# CY8C4248AZI_L485 register map
File version: 0.1
PSoC 4200L
Registers are 32-bit, read-write, no defined reset value unless marked. A register's access mark holds for its fields unless they carry their own. Offsets are from the block's base; lines under a group give offsets from that group; [hi:lo] are bit positions; {n}, {i} and the like mark numbered series; 'fields as' and 'values as' point back to an identical list; <NAME> marks a mode.

## Memory map
0x00000000 Limit_Register
0x00000000 Timer_Period_Reset
0x00000000 DMAC — DMAC Registers
0x00000000 Timer_Rotor_Delay
0x00000000 CAN
0x00000000 UART — Serial Communication Block
0x00000000 TMC6100_SPI — Serial Communication Block
0x00000000 Address_Register
0x00000000 Current_Sensor_I2C — Serial Communication Block

## Limit_Register
Base 0x00000000
0x400F0064 Limit_Register_STATUS_REG 8-bit
0x400F0084 Limit_Register_MASK_REG 8-bit
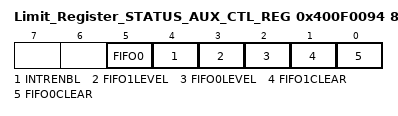
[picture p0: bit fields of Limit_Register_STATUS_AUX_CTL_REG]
0x400F0094 Limit_Register_STATUS_AUX_CTL_REG 8-bit
  [5] FIFO0 — FIFO0 clear
    1=ENABLED (Enable counter); 0=DISABLED (Disable counter)
  [4] INTRENBL — Enables or disables the Interrupt
    1=ENABLED (Interrupt enabled); 0=DISABLED (Interrupt disabled)
  [3] FIFO1LEVEL — FIFO level
    1=ENABLED (FIFO LVL: input mode: FIFO at least 1/2 empty; output mode: FIFO at least 1/2 full); 0=DISABLED (FIFO LVL: input mode: FIFO not full; output mode: FIFO not empty)
  [2] FIFO0LEVEL — FIFO level
    values as FIFO1LEVEL
  [1] FIFO1CLEAR — FIFO clear
    1=ENABLED (Clear FIFO state); 0=DISABLED (Normal FIFO operation)
  [0] FIFO0CLEAR — FIFO clear
    values as FIFO1CLEAR

## Timer_Period_Reset
Base 0x00000000
0x400F0006 Timer_Period_Reset_COUNTER 8-bit — UDB.A0 - Current Down Counter Value
0x400F0026 Timer_Period_Reset_PERIOD 8-bit — UDB.D0 - Assigned Period
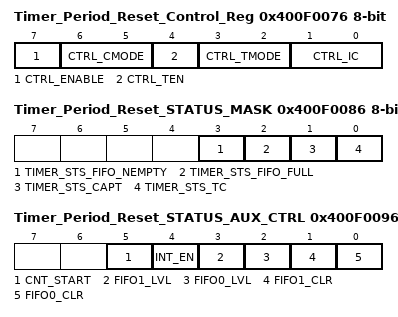
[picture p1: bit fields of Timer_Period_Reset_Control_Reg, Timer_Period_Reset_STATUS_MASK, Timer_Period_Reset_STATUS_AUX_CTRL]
0x400F0076 Timer_Period_Reset_Control_Reg 8-bit — UDB Control Register - Assigned Control Register Value
  [7] CTRL_ENABLE — Enable the Timer
  [6:5] CTRL_CMODE — Capture Mode
  [4] CTRL_TEN — Trigger Enable Bit
  [3:2] CTRL_TMODE — Trigger Mode
  [1:0] CTRL_IC — Interrupt Count
0x400F0086 Timer_Period_Reset_STATUS_MASK 8-bit — UDB Status bits Interrupt Mask Enable Register
  [3] TIMER_STS_FIFO_NEMPTY ro — FIFO Empty status
  [2] TIMER_STS_FIFO_FULL ro — FIFO Full Status
  [1] TIMER_STS_CAPT ro — Enables the Interrupt on Capture
  [0] TIMER_STS_TC ro — Enables the Interrupt on TC
0x400F0096 Timer_Period_Reset_STATUS_AUX_CTRL 8-bit — UDB Auxilliary Control Register
  [5] CNT_START — FIFO0 clear
    0=E_CNT_START0 (Disable counter); 1=E_CNT_START1 (Enable counter)
  [4] INT_EN
    0=E_INT_EN0 (Interrupt disabled); 1=E_INT_EN1 (Interrupt enabled)
  [3] FIFO1_LVL — FIFO level
    0=E_FIFO_LVL_0 (FIFO LVL: input mode: FIFO not full; output mode: FIFO not empty); 1=E_FIFO_LVL_1 (FIFO LVL: input mode: FIFO at least 1/2 empty; output mode: FIFO at least 1/2 full)
  [2] FIFO0_LVL — FIFO level
    values as FIFO1_LVL
  [1] FIFO1_CLR — FIFO1 clear
    0=E_FIFO_CLR_0 (Normal FIFO operation); 1=E_FIFO_CLR_1 (Clear FIFO state)
  [0] FIFO0_CLR — FIFO0 clear
    values as FIFO1_CLR

## Timer_Rotor_Delay
Base 0x00000000
0x400F0004 Timer_Rotor_Delay_COUNTER 16-bit — UDB.A0 - Current Down Counter Value
0x400F0024 Timer_Rotor_Delay_PERIOD 16-bit — UDB.D0 - Assigned Period
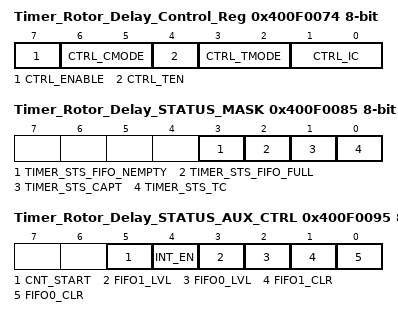
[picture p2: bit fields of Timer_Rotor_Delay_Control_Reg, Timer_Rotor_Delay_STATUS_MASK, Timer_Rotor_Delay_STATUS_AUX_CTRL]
0x400F0074 Timer_Rotor_Delay_Control_Reg 8-bit — UDB Control Register - Assigned Control Register Value
  [7] CTRL_ENABLE — Enable the Timer
  [6:5] CTRL_CMODE — Capture Mode
  [4] CTRL_TEN — Trigger Enable Bit
  [3:2] CTRL_TMODE — Trigger Mode
  [1:0] CTRL_IC — Interrupt Count
0x400F0085 Timer_Rotor_Delay_STATUS_MASK 8-bit — UDB Status bits Interrupt Mask Enable Register
  [3] TIMER_STS_FIFO_NEMPTY ro — FIFO Empty status
  [2] TIMER_STS_FIFO_FULL ro — FIFO Full Status
  [1] TIMER_STS_CAPT ro — Enables the Interrupt on Capture
  [0] TIMER_STS_TC ro — Enables the Interrupt on TC
0x400F0095 Timer_Rotor_Delay_STATUS_AUX_CTRL 8-bit — UDB Auxilliary Control Register
  [5] CNT_START — FIFO0 clear
    0=E_CNT_START0 (Disable counter); 1=E_CNT_START1 (Enable counter)
  [4] INT_EN
    0=E_INT_EN0 (Interrupt disabled); 1=E_INT_EN1 (Interrupt enabled)
  [3] FIFO1_LVL — FIFO level
    0=E_FIFO_LVL_0 (FIFO LVL: input mode: FIFO not full; output mode: FIFO not empty); 1=E_FIFO_LVL_1 (FIFO LVL: input mode: FIFO at least 1/2 empty; output mode: FIFO at least 1/2 full)
  [2] FIFO0_LVL — FIFO level
    values as FIFO1_LVL
  [1] FIFO1_CLR — FIFO1 clear
    0=E_FIFO_CLR_0 (Normal FIFO operation); 1=E_FIFO_CLR_1 (Clear FIFO state)
  [0] FIFO0_CLR — FIFO0 clear
    values as FIFO1_CLR
